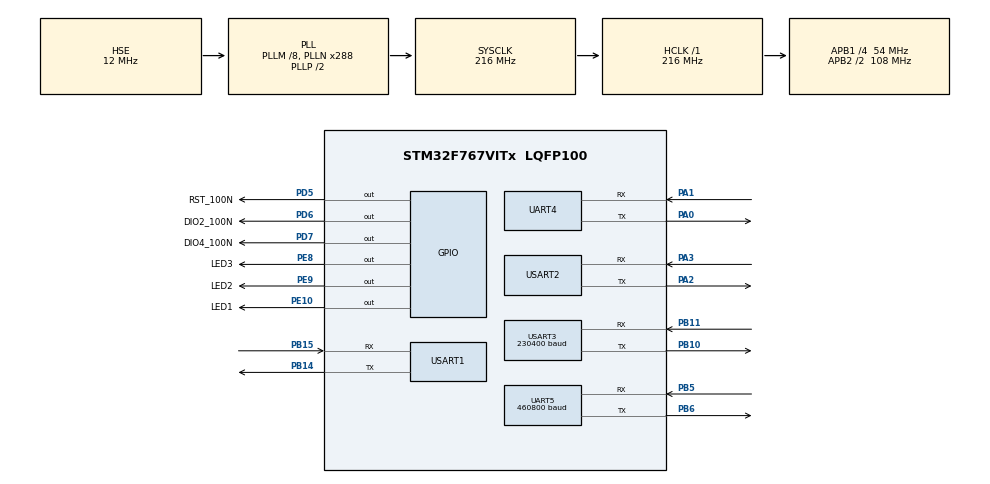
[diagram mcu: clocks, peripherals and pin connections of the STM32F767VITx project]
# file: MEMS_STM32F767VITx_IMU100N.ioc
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Dma.Request0=USART3_TX
Dma.Request1=UART5_TX
Dma.Request2=UART5_RX
Dma.UART5_RX.2.Direction=DMA_PERIPH_TO_MEMORY
Dma.UART5_RX.2.FIFOMode=DMA_FIFOMODE_DISABLE
Dma.UART5_RX.2.Instance=DMA1_Stream0
Dma.UART5_RX.2.MemDataAlignment=DMA_MDATAALIGN_BYTE
Dma.UART5_RX.2.MemInc=DMA_MINC_ENABLE
Dma.UART5_RX.2.Mode=DMA_CIRCULAR
Dma.UART5_RX.2.PeriphDataAlignment=DMA_PDATAALIGN_BYTE
Dma.UART5_RX.2.PeriphInc=DMA_PINC_DISABLE
Dma.UART5_RX.2.Priority=DMA_PRIORITY_LOW
Dma.UART5_TX.1.Direction=DMA_MEMORY_TO_PERIPH
Dma.UART5_TX.1.FIFOMode=DMA_FIFOMODE_DISABLE
Dma.UART5_TX.1.Instance=DMA1_Stream7
Dma.UART5_TX.1.MemDataAlignment=DMA_MDATAALIGN_BYTE
Dma.UART5_TX.1.MemInc=DMA_MINC_ENABLE
Dma.UART5_TX.1.Mode=DMA_NORMAL
Dma.UART5_TX.1.PeriphDataAlignment=DMA_PDATAALIGN_BYTE
Dma.UART5_TX.1.PeriphInc=DMA_PINC_DISABLE
Dma.UART5_TX.1.Priority=DMA_PRIORITY_LOW
Dma.USART3_TX.0.Direction=DMA_MEMORY_TO_PERIPH
Dma.USART3_TX.0.FIFOMode=DMA_FIFOMODE_DISABLE
Dma.USART3_TX.0.Instance=DMA1_Stream3
Dma.USART3_TX.0.MemDataAlignment=DMA_MDATAALIGN_BYTE
Dma.USART3_TX.0.MemInc=DMA_MINC_ENABLE
Dma.USART3_TX.0.Mode=DMA_NORMAL
Dma.USART3_TX.0.PeriphDataAlignment=DMA_PDATAALIGN_BYTE
Dma.USART3_TX.0.PeriphInc=DMA_PINC_DISABLE
Dma.USART3_TX.0.Priority=DMA_PRIORITY_LOW
Mcu.Family=STM32F7
Mcu.Name=STM32F767VITx
Mcu.Package=LQFP100
NVIC.DMA1_Stream0_IRQn=true\:0\:0\:false\:false\:true\:false
NVIC.DMA1_Stream3_IRQn=true\:0\:0\:false\:false\:true\:false
NVIC.DMA1_Stream7_IRQn=true\:0\:0\:false\:false\:true\:false
NVIC.PriorityGroup=NVIC_PRIORITYGROUP_4
NVIC.TIM6_DAC_IRQn=true\:0\:0\:false\:false\:true\:true
NVIC.UART4_IRQn=true\:0\:0\:false\:false\:true\:true
NVIC.UART5_IRQn=true\:0\:0\:false\:false\:true\:true
NVIC.USART1_IRQn=true\:0\:0\:false\:false\:true\:true
NVIC.USART2_IRQn=true\:0\:0\:false\:false\:true\:true
NVIC.USART3_IRQn=true\:0\:0\:false\:false\:true\:true
PA0/WKUP.Mode=Asynchronous
PA0/WKUP.Signal=UART4_TX
PA1.Mode=Asynchronous
PA1.Signal=UART4_RX
PA13.Mode=Serial_Wire
PA13.Signal=SYS_JTMS-SWDIO
PA14.Mode=Serial_Wire
PA14.Signal=SYS_JTCK-SWCLK
PA2.Mode=Asynchronous
PA2.Signal=USART2_TX
PA3.Mode=Asynchronous
PA3.Signal=USART2_RX
PB10.Mode=Asynchronous
PB10.Signal=USART3_TX
PB11.Mode=Asynchronous
PB11.Signal=USART3_RX
PB14.Mode=Asynchronous
PB14.Signal=USART1_TX
PB15.Mode=Asynchronous
PB15.Signal=USART1_RX
PB5.Mode=Asynchronous
PB5.Signal=UART5_RX
PB6.Mode=Asynchronous
PB6.Signal=UART5_TX
PD5.GPIO_Label=RST_100N
PD5.Signal=GPIO_Output
PD6.GPIO_Label=DIO2_100N
PD6.Signal=GPIO_Output
PD7.GPIO_Label=DIO4_100N
PD7.Signal=GPIO_Output
PE10.GPIO_Label=LED1
PE10.Signal=GPIO_Output
PE8.GPIO_Label=LED3
PE8.Signal=GPIO_Output
PE9.GPIO_Label=LED2
PE9.Signal=GPIO_Output
PH0/OSC_IN.Mode=HSE-External-Oscillator
PH0/OSC_IN.Signal=RCC_OSC_IN
PH1/OSC_OUT.Mode=HSE-External-Oscillator
PH1/OSC_OUT.Signal=RCC_OSC_OUT
ProjectManager.HeapSize=0x200
ProjectManager.StackSize=0x2800
ProjectManager.TargetToolchain=MDK-ARM V5
RCC.AHBFreq_Value=216000000
RCC.APB1CLKDivider=RCC_HCLK_DIV4
RCC.APB1Freq_Value=54000000
RCC.APB1TimFreq_Value=108000000
RCC.APB2CLKDivider=RCC_HCLK_DIV2
RCC.APB2Freq_Value=108000000
RCC.APB2TimFreq_Value=216000000
RCC.CortexFreq_Value=216000000
RCC.HCLKFreq_Value=216000000
RCC.HSE_VALUE=12000000
RCC.HSI_VALUE=16000000
RCC.LSE_VALUE=32768
RCC.PLLM=8
RCC.PLLN=288
RCC.PLLSourceVirtual=RCC_PLLSOURCE_HSE
RCC.SYSCLKFreq_VALUE=216000000
RCC.SYSCLKSource=RCC_SYSCLKSOURCE_PLLCLK
RCC.USBFreq_Value=216000000
RCC.VCOOutputFreq_Value=432000000
TIM6.Period=99
TIM6.Prescaler=10799
UART5.BaudRate=460800
USART1.VirtualMode-Asynchronous=VM_ASYNC
USART2.VirtualMode-Asynchronous=VM_ASYNC
USART3.BaudRate=230400
USART3.VirtualMode-Asynchronous=VM_ASYNC
VP_TIM6_VS_ClockSourceINT.Mode=Enable_Timer
board=MEMS_STM32F767VITx_IMU100N

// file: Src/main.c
/**
  ******************************************************************************
  * @file           : main.c
  * @brief          : Main program body
  ******************************************************************************
  ** This notice applies to any and all portions of this file
  * that are not between comment pairs USER CODE BEGIN and
  * USER CODE END. Other portions of this file, whether
  * inserted by the user or by software development tools
  * are owned by their respective copyright owners.
  *
  * COPYRIGHT(c) 2019 STMicroelectronics
  *
  * Redistribution and use in source and binary forms, with or without modification,
  * are permitted provided that the following conditions are met:
  *   1. Redistributions of source code must retain the above copyright notice,
  *      this list of conditions and the following disclaimer.
  *   2. Redistributions in binary form must reproduce the above copyright notice,
  *      this list of conditions and the following disclaimer in the documentation
  *      and/or other materials provided with the distribution.
  *   3. Neither the name of STMicroelectronics nor the names of its contributors
  *      may be used to endorse or promote products derived from this software
  *      without specific prior written permission.
  *
  * THIS SOFTWARE IS PROVIDED BY THE COPYRIGHT HOLDERS AND CONTRIBUTORS "AS IS"
  * AND ANY EXPRESS OR IMPLIED WARRANTIES, INCLUDING, BUT NOT LIMITED TO, THE
  * IMPLIED WARRANTIES OF MERCHANTABILITY AND FITNESS FOR A PARTICULAR PURPOSE ARE
  * DISCLAIMED. IN NO EVENT SHALL THE COPYRIGHT HOLDER OR CONTRIBUTORS BE LIABLE
  * FOR ANY DIRECT, INDIRECT, INCIDENTAL, SPECIAL, EXEMPLARY, OR CONSEQUENTIAL
  * DAMAGES (INCLUDING, BUT NOT LIMITED TO, PROCUREMENT OF SUBSTITUTE GOODS OR
  * SERVICES; LOSS OF USE, DATA, OR PROFITS; OR BUSINESS INTERRUPTION) HOWEVER
  * CAUSED AND ON ANY THEORY OF LIABILITY, WHETHER IN CONTRACT, STRICT LIABILITY,
  * OR TORT (INCLUDING NEGLIGENCE OR OTHERWISE) ARISING IN ANY WAY OUT OF THE USE
  * OF THIS SOFTWARE, EVEN IF ADVISED OF THE POSSIBILITY OF SUCH DAMAGE.
  *
  ******************************************************************************
  */
#include "main.h"
#include "stm32f7xx_hal.h"
#include "dma.h"
#include "tim.h"
#include "usart.h"
#include "gpio.h"

/* USER CODE BEGIN Includes */
#include "MainEntry.h"
/* USER CODE END Includes */

/* USER CODE BEGIN PV */
/* Private variables ---------------------------------------------------------*/

/* USER CODE END PV */

void SystemClock_Config(void);

/* USER CODE BEGIN PFP */
/* Private function prototypes -----------------------------------------------*/

/* USER CODE END PFP */

int main(void)
{

  /* MCU Configuration----------------------------------------------------------*/

  /* Reset of all peripherals, Initializes the Flash interface and the Systick. */
  HAL_Init();

  /* Configure the system clock */
  SystemClock_Config();

  /* Initialize all configured peripherals */
  MX_GPIO_Init();
  MX_DMA_Init();
  MX_USART1_UART_Init();
  MX_USART2_UART_Init();
  MX_USART3_UART_Init();
  MX_UART4_Init();
  MX_TIM6_Init();
  MX_UART5_Init();
  /* USER CODE BEGIN 2 */
  MainEntry();
  /* USER CODE END 2 */

  /* Infinite loop */
  while (1)
  {

  }

}

void SystemClock_Config(void)
{

  RCC_OscInitTypeDef RCC_OscInitStruct;
  RCC_ClkInitTypeDef RCC_ClkInitStruct;
  RCC_PeriphCLKInitTypeDef PeriphClkInitStruct;

    /**Configure the main internal regulator output voltage
    */
  __HAL_RCC_PWR_CLK_ENABLE();

  __HAL_PWR_VOLTAGESCALING_CONFIG(PWR_REGULATOR_VOLTAGE_SCALE1);

    /**Initializes the CPU, AHB and APB busses clocks
    */
  RCC_OscInitStruct.OscillatorType = RCC_OSCILLATORTYPE_HSE;
  RCC_OscInitStruct.HSEState = RCC_HSE_ON;
  RCC_OscInitStruct.PLL.PLLState = RCC_PLL_ON;
  RCC_OscInitStruct.PLL.PLLSource = RCC_PLLSOURCE_HSE;
  RCC_OscInitStruct.PLL.PLLM = 8;
  RCC_OscInitStruct.PLL.PLLN = 288;
  RCC_OscInitStruct.PLL.PLLP = RCC_PLLP_DIV2;
  RCC_OscInitStruct.PLL.PLLQ = 2;
  if (HAL_RCC_OscConfig(&RCC_OscInitStruct) != HAL_OK)
  {
    _Error_Handler(__FILE__, __LINE__);
  }

    /**Activate the Over-Drive mode
    */
  if (HAL_PWREx_EnableOverDrive() != HAL_OK)
  {
    _Error_Handler(__FILE__, __LINE__);
  }

    /**Initializes the CPU, AHB and APB busses clocks
    */
  RCC_ClkInitStruct.ClockType = RCC_CLOCKTYPE_HCLK|RCC_CLOCKTYPE_SYSCLK
                              |RCC_CLOCKTYPE_PCLK1|RCC_CLOCKTYPE_PCLK2;
  RCC_ClkInitStruct.SYSCLKSource = RCC_SYSCLKSOURCE_PLLCLK;
  RCC_ClkInitStruct.AHBCLKDivider = RCC_SYSCLK_DIV1;
  RCC_ClkInitStruct.APB1CLKDivider = RCC_HCLK_DIV4;
  RCC_ClkInitStruct.APB2CLKDivider = RCC_HCLK_DIV2;

  if (HAL_RCC_ClockConfig(&RCC_ClkInitStruct, FLASH_LATENCY_7) != HAL_OK)
  {
    _Error_Handler(__FILE__, __LINE__);
  }

  PeriphClkInitStruct.PeriphClockSelection = RCC_PERIPHCLK_USART1|RCC_PERIPHCLK_USART2
                              |RCC_PERIPHCLK_USART3|RCC_PERIPHCLK_UART4
                              |RCC_PERIPHCLK_UART5;
  PeriphClkInitStruct.Usart1ClockSelection = RCC_USART1CLKSOURCE_PCLK2;
  PeriphClkInitStruct.Usart2ClockSelection = RCC_USART2CLKSOURCE_PCLK1;
  PeriphClkInitStruct.Usart3ClockSelection = RCC_USART3CLKSOURCE_PCLK1;
  PeriphClkInitStruct.Uart4ClockSelection = RCC_UART4CLKSOURCE_PCLK1;
  PeriphClkInitStruct.Uart5ClockSelection = RCC_UART5CLKSOURCE_PCLK1;
  if (HAL_RCCEx_PeriphCLKConfig(&PeriphClkInitStruct) != HAL_OK)
  {
    _Error_Handler(__FILE__, __LINE__);
  }

    /**Configure the Systick interrupt time
    */
  HAL_SYSTICK_Config(HAL_RCC_GetHCLKFreq()/1000);

    /**Configure the Systick
    */
  HAL_SYSTICK_CLKSourceConfig(SYSTICK_CLKSOURCE_HCLK);

  /* SysTick_IRQn interrupt configuration */
  HAL_NVIC_SetPriority(SysTick_IRQn, 0, 0);
}

void _Error_Handler(char *file, int line)
{
  while(1)
  {
  }
}

/************************ (C) COPYRIGHT STMicroelectronics *****END OF FILE****/
